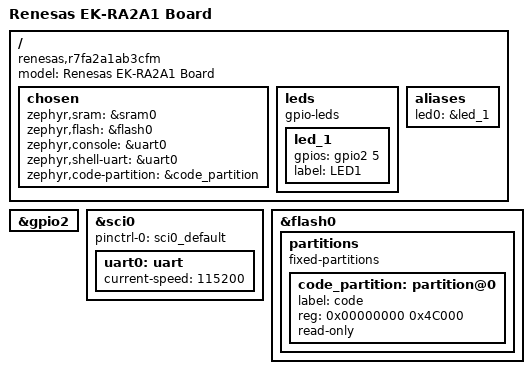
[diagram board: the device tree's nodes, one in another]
/*
 * Copyright (c) 2024 TOKITA Hiroshi
 * SPDX-License-Identifier: Apache-2.0
 */

/dts-v1/;

#include <renesas/ra/ra2/r7fa2a1ab3cfm.dtsi>
#include <zephyr/dt-bindings/gpio/gpio.h>

#include "ek_ra2a1-pinctrl.dtsi"

/ {
	model = "Renesas EK-RA2A1 Board";
	compatible = "renesas,r7fa2a1ab3cfm";

	chosen {
		zephyr,sram = &sram0;
		zephyr,flash = &flash0;
		zephyr,console = &uart0;
		zephyr,shell-uart = &uart0;
		zephyr,code-partition = &code_partition;
	};

	leds {
		compatible = "gpio-leds";
		led_1: led_1 {
			gpios = <&gpio2 5 GPIO_ACTIVE_HIGH>;
			label = "LED1";
		};
	};

	aliases {
		led0 = &led_1;
	};
};


&gpio2 {
	status = "okay";
};

&sci0 {
	pinctrl-0 = <&sci0_default>;
	pinctrl-names = "default";
	status = "okay";
	uart0: uart {
		current-speed = <115200>;
		status = "okay";
	};
};

&flash0 {
       partitions {
               compatible = "fixed-partitions";
               #address-cells = <1>;
               #size-cells = <1>;

               code_partition: partition@0 {
                       label = "code";
                       reg = <0x00000000 0x4C000>;
                       read-only;
               };
       };
};
